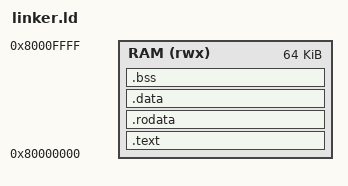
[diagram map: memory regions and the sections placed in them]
OUTPUT_ARCH(riscv)
ENTRY(_start)

MEMORY
{
    RAM (rwx) : ORIGIN = 0x80000000, LENGTH = 64K
}

SECTIONS
{
    .text : {
        *(.text.init)
        *(.text*)
    } > RAM

    .rodata : { *(.rodata*) } > RAM
    .data   : { *(.data*) } > RAM
    .bss    : { *(.bss*) *(COMMON) } > RAM

    . = ALIGN(16);
    . += 0x1000;
    _stack_top = ORIGIN(RAM) + LENGTH(RAM);
}
